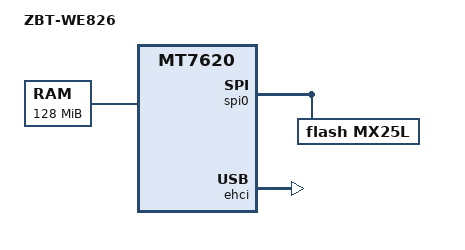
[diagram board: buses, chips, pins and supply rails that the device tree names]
/*
 * Copyright (c) 2013, Alexander A. Mityaev <sansan@adm.ua>
 */

/dts-v1/;
/include/ "mt7620a.dtsi"

/ {
	compatible = "mtk,mt7620-soc";
	model = "ZBT-WE826";

	memory {
		/* 128MB RAM */
	       	device_type = "memory";
		reg = < 0x80000000 0x8000000 >;
	};

	soc {
	    pbus {
		spi0 {
			flash {
				compatible = "flash,mx25l";
				spi-chipselect = <0>;
				#address-cells = <1>;
				#size-cells = <1>;

				slice@0x30000 {
	       				reg = <0x30000 0x10000>;
				        label = "config";
					read-only;
				};
			};
		};

		uart0: uart@c00 {
			current-speed = <115200>;
		};
	    };
	    ehci { status = "okay"; };
	};

	aliases {
		uartlite = &uart0;
	};

	chosen {
		bootargs = "-v";
		stdin = &uart0;
		stdout = &uart0;
	};

};

